# AT90CAN128 register map
Vendor: Atmel; File version: 1.0
CPU: other r0p0, little endian, no MPU, no FPU, 4 interrupt priority bits
Registers are 8-bit, read-write, reset 0x0 unless marked. A register's access mark holds for its fields unless they carry their own. Offsets are from the block's base; lines under a group give offsets from that group; [hi:lo] are bit positions; {n}, {i} and the like mark numbered series; 'fields as' and 'values as' point back to an identical list; <NAME> marks a mode.

## Memory map
0x00000000 FUSE size 0x3 — Fuses
0x00000000 LOCKBIT size 0x1 — Lockbits
0x00000020 PORTA size 0x3 — I/O Port
0x00000023 PORTB size 0x3 — I/O Port
0x00000026 PORTC size 0x3 — I/O Port
0x00000029 PORTD size 0x3 — I/O Port
0x0000002C PORTE size 0x3 — I/O Port
0x0000002F PORTF size 0x3 — I/O Port
0x00000032 PORTG size 0x3 — I/O Port
0x00000035 TC0 blocks up to offset 0x3A — Timer/Counter, 8-bit
0x00000036 TC1 blocks up to offset 0x58 — Timer/Counter, 16-bit
0x00000037 TC2 blocks up to offset 0x80 — Timer/Counter, 8-bit Async
0x00000038 TC3 blocks up to offset 0x66 — Timer/Counter, 16-bit
0x0000003C EXINT blocks up to offset 0x2F — External Interrupts
0x0000003E CPU blocks up to offset 0x38 — CPU Registers
0x0000003F EEPROM size 0x4
0x0000004C SPI size 0x3 — Serial Peripheral Interface
0x00000050 AC blocks up to offset 0x30 — Analog Comparator
0x00000051 JTAG blocks up to offset 0x5 — JTAG Interface
0x00000057 BOOT_LOAD size 0x1 — Bootloader
0x00000060 WDT size 0x1 — Watchdog Timer
0x00000078 ADC blocks up to offset 0x7 — Analog-to-Digital Converter
0x000000B8 TWI size 0x5 — Two Wire Serial Interface
0x000000C0 USART0 blocks up to offset 0x7 — USART
0x000000C8 USART1 blocks up to offset 0x7 — USART
0x000000D8 CAN size 0x23 — Controller Area Network

## Interrupts
0 RESET (CPU) — External Pin, Power-on Reset, Brown-out Reset, Watchdog Reset and JTAG AVR Reset
{n+1} INT{n} (CPU) (n=0..7) — External Interrupt Request {n}
9 TIMER2_COMP (CPU) — Timer/Counter2 Compare Match
10 TIMER2_OVF (CPU) — Timer/Counter2 Overflow
11 TIMER1_CAPT (CPU) — Timer/Counter1 Capture Event
12 TIMER1_COMPA (CPU) — Timer/Counter1 Compare Match A
13 TIMER1_COMPB (CPU) — Timer/Counter Compare Match B
14 TIMER1_COMPC (CPU) — Timer/Counter1 Compare Match C
15 TIMER1_OVF (CPU) — Timer/Counter1 Overflow
16 TIMER0_COMP (CPU) — Timer/Counter0 Compare Match
17 TIMER0_OVF (CPU) — Timer/Counter0 Overflow
18 CANIT (CPU) — CAN Transfer Complete or Error
19 OVRIT (CPU) — CAN Timer Overrun
20 SPI_STC (CPU) — SPI Serial Transfer Complete
21 USART0_RX (CPU) — USART0, Rx Complete
22 USART0_UDRE (CPU) — USART0 Data Register Empty
23 USART0_TX (CPU) — USART0, Tx Complete
24 ANALOG_COMP (CPU) — Analog Comparator
25 ADC (CPU) — ADC Conversion Complete
26 EE_READY (CPU) — EEPROM Ready
27 TIMER3_CAPT (CPU) — Timer/Counter3 Capture Event
28 TIMER3_COMPA (CPU) — Timer/Counter3 Compare Match A
29 TIMER3_COMPB (CPU) — Timer/Counter3 Compare Match B
30 TIMER3_COMPC (CPU) — Timer/Counter3 Compare Match C
31 TIMER3_OVF (CPU) — Timer/Counter3 Overflow
32 USART1_RX (CPU) — USART1, Rx Complete
33 USART1_UDRE (CPU) — USART1, Data Register Empty
34 USART1_TX (CPU) — USART1, Tx Complete
35 TWI (CPU) — 2-wire Serial Interface
36 SPM_READY (CPU) — Store Program Memory Read

## AC — Analog Comparator
Base 0x00000050
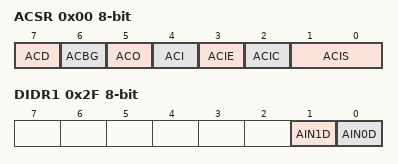
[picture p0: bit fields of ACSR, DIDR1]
0x00 ACSR — Analog Comparator Control And Status Register
  [7] ACD — Analog Comparator Disable
  [6] ACBG — Analog Comparator Bandgap Select
  [5] ACO — Analog Compare Output
  [4] ACI — Analog Comparator Interrupt Flag
  [3] ACIE — Analog Comparator Interrupt Enable
  [2] ACIC — Analog Comparator Input Capture Enable
  [1:0] ACIS — Analog Comparator Interrupt Mode Select bits
    0=Interrupt on Toggle; 2=Interrupt on Falling Edge; 3=Interrupt on Rising Edge
0x2B ADCSRB — ADC Control and Status Register B
  [6] ACME — Analog Comparator Multiplexer Enable
0x2F DIDR1
  [1] AIN1D — AIN1 Digital Input Disable
  [0] AIN0D — AIN0 Digital Input Disable

## ADC — Analog-to-Digital Converter
Base 0x00000078
0x00 ADC 16-bit (reset mask 0xFF) — ADC Data Register Bytes
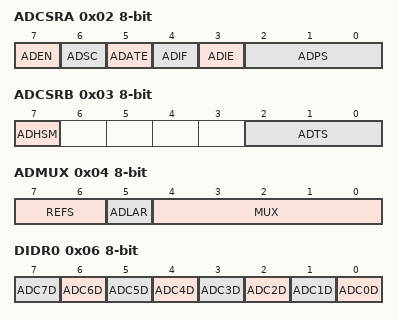
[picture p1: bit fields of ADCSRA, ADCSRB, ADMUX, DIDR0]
0x02 ADCSRA — The ADC Control and Status register
  [7] ADEN — ADC Enable
  [6] ADSC — ADC Start Conversion
  [5] ADATE — ADC Auto Trigger Enable
  [4] ADIF — ADC Interrupt Flag
  [3] ADIE — ADC Interrupt Enable
  [2:0] ADPS — ADC Prescaler Select Bits
    0=2; 1=2; 2=4; 3=8; 4=16; 5=32; 6=64; 7=128
0x03 ADCSRB — ADC Control and Status Register B
  [7] ADHSM — ADC High Speed Mode
  [2:0] ADTS — ADC Auto Trigger Sources
    0=Free Running mode; 1=Analog Comparator; 2=External Interrupt Request 0; 3=Timer/Counter0 Compare Match A; 4=Timer/Counter0 Overflow; 5=Timer/Counter1 Compare Match B; 6=Timer/Counter1 Overflow; 7=Timer/Counter1 Capture Event
0x04 ADMUX — The ADC multiplexer Selection Register
  [7:6] REFS — Reference Selection Bits
    0=AREF, Internal Vref turned off; 1=AVCC with external capacitor at AREF pin; 3=Internal 2.56V Voltage Reference with external capacitor at AREF pin
  [5] ADLAR — Left Adjust Result
  [4:0] MUX — Analog Channel and Gain Selection Bits
0x06 DIDR0 — Digital Input Disable Register 1
  [n] ADC{n}D (n=0..7) — ADC{n} Digital input Disable
